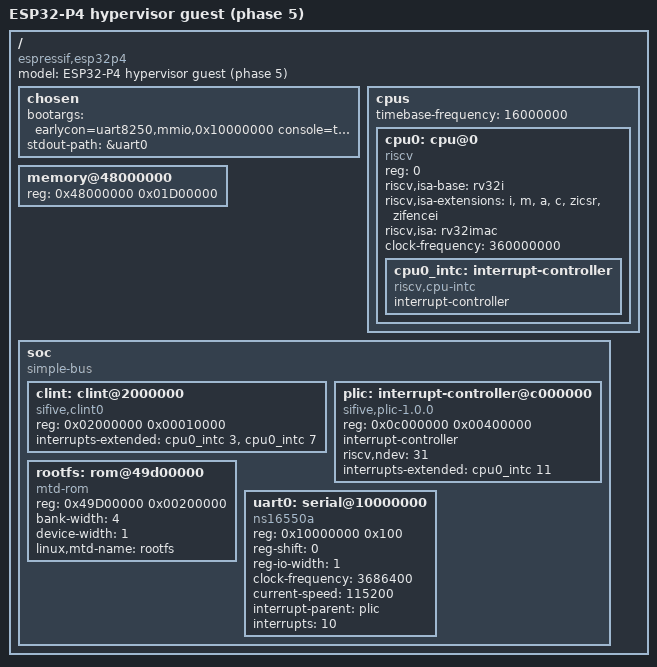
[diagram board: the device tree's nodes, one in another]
/*
 * ESP32-P4 hypervisor guest - PHASE 5
 *
 * Phase 4 plus a root filesystem that is not in RAM.
 *
 * The monitor copies a romfs image out of the "rootfs" flash partition into a
 * reserved PSRAM window at 0x49D00000 and this node describes that window as
 * an mtd-rom device, so the kernel mounts / from it with root=mtd0. That
 * replaces the initramfs, which pinned ~2.4 MB of ramfs for the whole uptime
 * and carried a second copy of the rootfs inside the kernel image.
 *
 * The window is above memory{} and below the DTB, all three inside the single
 * PMP grant over 0x48000000-0x4A000000:
 *
 *   0x48000000  29 MB   memory{}         Linux
 *   0x49D00000   2 MB   rom@49d00000     romfs image (~1.1 MB used)
 *   0x49F00000   1 MB   -                DTB
 *
 * No new traps for this phase: the guest reads the romfs with ordinary loads
 * from granted memory, so the monitor never sees them.
 */
/dts-v1/;

/ {
	#address-cells = <1>;
	#size-cells = <1>;
	compatible = "espressif,esp32p4";
	model = "ESP32-P4 hypervisor guest (phase 5)";

	chosen {
		/*
		 * earlycon  -> output before drivers probe
		 * console=  -> hand over to the real 8250 driver once it probes
		 * keep_bootcon -> keep BOTH active, so if the handover breaks
		 *                 you still see output. Drop it once stable.
		 */
		bootargs = "earlycon=uart8250,mmio,0x10000000 console=ttyS0 root=mtd0 rootfstype=romfs ro";
		stdout-path = &uart0;
	};

	cpus {
		#address-cells = <1>;
		#size-cells = <0>;
		timebase-frequency = <16000000>;

		cpu0: cpu@0 {
			device_type = "cpu";
			compatible = "riscv";
			reg = <0>;
			status = "okay";

			riscv,isa-base = "rv32i";
			riscv,isa-extensions = "i", "m", "a", "c",
					       "zicsr", "zifencei";
			riscv,isa = "rv32imac";
			clock-frequency = <360000000>;

			cpu0_intc: interrupt-controller {
				#interrupt-cells = <1>;
				compatible = "riscv,cpu-intc";
				interrupt-controller;
			};
		};
	};

	memory@48000000 {
		device_type = "memory";
	/*
		 * 29 MB. The romfs window and the DTB take the rest of the
		 * 32 MB grant and must stay outside this node, or Linux will
		 * allocate over the filesystem it is running from.
		 */
		reg = <0x48000000 0x01D00000>;
	};

	soc {
		#address-cells = <1>;
		#size-cells = <1>;
		compatible = "simple-bus";
		ranges;

		clint: clint@2000000 {
			compatible = "sifive,clint0", "riscv,clint0";
			reg = <0x02000000 0x00010000>;
			interrupts-extended = <&cpu0_intc 3>,
					      <&cpu0_intc 7>;
		};

		plic: interrupt-controller@c000000 {
			compatible = "sifive,plic-1.0.0";
			reg = <0x0c000000 0x00400000>;
			interrupt-controller;
			#interrupt-cells = <1>;
			#address-cells = <0>;

			/*
			 * riscv,ndev = highest interrupt source number.
			 * Keep it small — it sizes the driver's tables and
			 * bounds how much shadow state you must maintain.
			 */
			riscv,ndev = <31>;

			/* one context: hart 0, M-mode external (bit 11) */
			interrupts-extended = <&cpu0_intc 11>;
		};


		/*
		 * physmap-core.c binds "mtd-rom" and requires bank-width. On a
		 * NOMMU kernel its ioremap is the identity, so reads land
		 * straight on the PSRAM window the monitor filled.
		 */
		rootfs: rom@49d00000 {
			compatible = "mtd-rom";
			reg = <0x49D00000 0x00200000>;
			bank-width = <4>;
			device-width = <1>;
			linux,mtd-name = "rootfs";
		};
		uart0: serial@10000000 {
			compatible = "ns16550a";
			reg = <0x10000000 0x100>;

			/* one byte between registers — simplest to emulate */
			reg-shift = <0>;
			reg-io-width = <1>;
l
			/*
			 * Baud is fiction: your monitor forwards bytes to the
			 * real UART0, which the ROM already set to 115200.
			 * This value only feeds the divisor Linux computes and
			 * then writes to registers you ignore.
			 */
			clock-frequency = <3686400>;
			current-speed = <115200>;

			interrupt-parent = <&plic>;
			interrupts = <10>;

			status = "okay";
		};
	};
};
